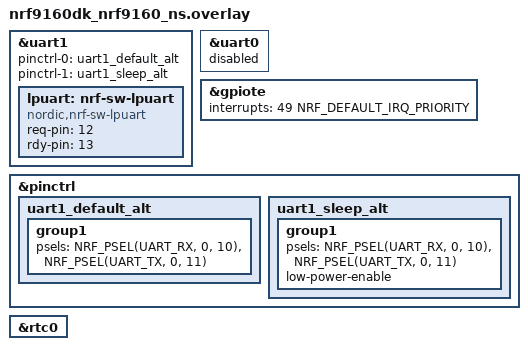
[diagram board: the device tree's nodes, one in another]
/* SPDX-License-Identifier: LicenseRef-Nordic-5-Clause */

&uart1 {
	status = "okay";

	pinctrl-0 = <&uart1_default_alt>;
	pinctrl-1 = <&uart1_sleep_alt>;
	pinctrl-names = "default", "sleep";
	lpuart: nrf-sw-lpuart {
		compatible = "nordic,nrf-sw-lpuart";
		status = "okay";
		req-pin = <12>;
		rdy-pin = <13>;
	};
};

&uart0 {
	status = "disabled";
};

&gpiote {
	interrupts = <49 NRF_DEFAULT_IRQ_PRIORITY>;
};

&pinctrl {
	uart1_default_alt: uart1_default_alt {
		group1 {
			psels = <NRF_PSEL(UART_RX, 0, 10)>,
				<NRF_PSEL(UART_TX, 0, 11)>;
		};
	};

	uart1_sleep_alt: uart1_sleep_alt {
		group1 {
			psels = <NRF_PSEL(UART_RX, 0, 10)>,
				<NRF_PSEL(UART_TX, 0, 11)>;
			low-power-enable;
		};
	};
};

&rtc0 {
	status = "okay";
};
